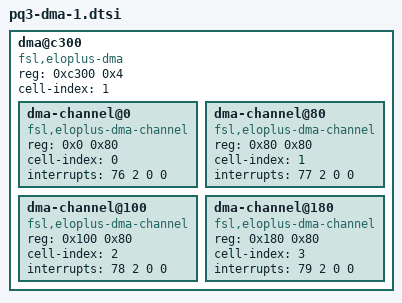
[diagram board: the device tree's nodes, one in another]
dma@c300 {
	#address-cells = <1>;
	#size-cells = <1>;
	compatible = "fsl,eloplus-dma";
	reg = <0xc300 0x4>;
	ranges = <0x0 0xc100 0x200>;
	cell-index = <1>;
	dma-channel@0 {
		compatible = "fsl,eloplus-dma-channel";
		reg = <0x0 0x80>;
		cell-index = <0>;
		interrupts = <76 2 0 0>;
	};
	dma-channel@80 {
		compatible = "fsl,eloplus-dma-channel";
		reg = <0x80 0x80>;
		cell-index = <1>;
		interrupts = <77 2 0 0>;
	};
	dma-channel@100 {
		compatible = "fsl,eloplus-dma-channel";
		reg = <0x100 0x80>;
		cell-index = <2>;
		interrupts = <78 2 0 0>;
	};
	dma-channel@180 {
		compatible = "fsl,eloplus-dma-channel";
		reg = <0x180 0x80>;
		cell-index = <3>;
		interrupts = <79 2 0 0>;
	};
};
